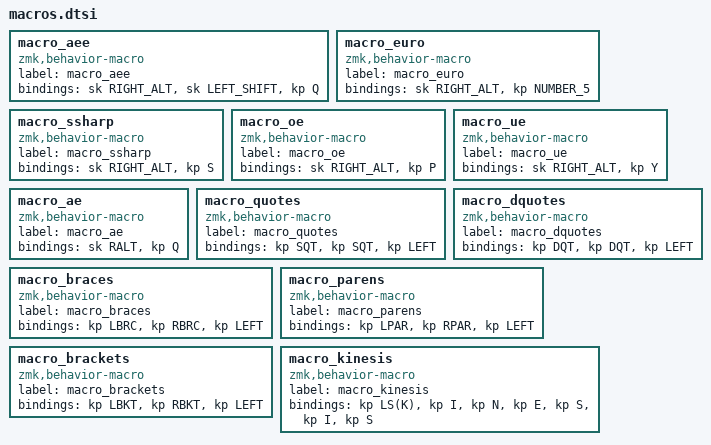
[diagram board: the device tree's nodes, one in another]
macro_aee: macro_aee{
compatible = "zmk,behavior-macro";
label = "macro_aee";
#binding-cells = <0>;
bindings = <&sk RIGHT_ALT>, <&sk LEFT_SHIFT>, <&kp Q>;
};
macro_euro: macro_euro{
compatible = "zmk,behavior-macro";
label = "macro_euro";
#binding-cells = <0>;
bindings = <&sk RIGHT_ALT>, <&kp NUMBER_5>;
};
macro_ssharp: macro_ssharp{
compatible = "zmk,behavior-macro";
label = "macro_ssharp";
#binding-cells = <0>;
bindings = <&sk RIGHT_ALT>, <&kp S>;
};
macro_oe: macro_oe{
compatible = "zmk,behavior-macro";
label = "macro_oe";
#binding-cells = <0>;
bindings = <&sk RIGHT_ALT>, <&kp P>;
};
macro_ue: macro_ue{
compatible = "zmk,behavior-macro";
label = "macro_ue";
#binding-cells = <0>;
bindings = <&sk RIGHT_ALT>, <&kp Y>;
};
macro_ae: macro_ae{
compatible = "zmk,behavior-macro";
label = "macro_ae";
#binding-cells = <0>;
bindings = <&sk RALT>, <&kp Q>;
};
macro_quotes: macro_quotes{
compatible = "zmk,behavior-macro";
label = "macro_quotes";
#binding-cells = <0>;
bindings = <&kp SQT>, <&kp SQT>, <&kp LEFT>;
};
macro_dquotes: macro_dquotes{
compatible = "zmk,behavior-macro";
label = "macro_dquotes";
#binding-cells = <0>;
bindings = <&kp DQT>, <&kp DQT>, <&kp LEFT>;
};
macro_braces: macro_braces{
compatible = "zmk,behavior-macro";
label = "macro_braces";
#binding-cells = <0>;
bindings = <&kp LBRC>, <&kp RBRC>, <&kp LEFT>;
};
macro_parens: macro_parens{
compatible = "zmk,behavior-macro";
label = "macro_parens";
#binding-cells = <0>;
bindings = <&kp LPAR>, <&kp RPAR>, <&kp LEFT>;
};
macro_brackets: macro_brackets{
compatible = "zmk,behavior-macro";
label = "macro_brackets";
#binding-cells = <0>;
bindings = <&kp LBKT>, <&kp RBKT>, <&kp LEFT>;
};
macro_kinesis: macro_kinesis{
compatible = "zmk,behavior-macro";
label = "macro_kinesis";
#binding-cells = <0>;
bindings = <&kp LS(K)>, <&kp I>, <&kp N>, <&kp E>, <&kp S>, <&kp I>, <&kp S>;
};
